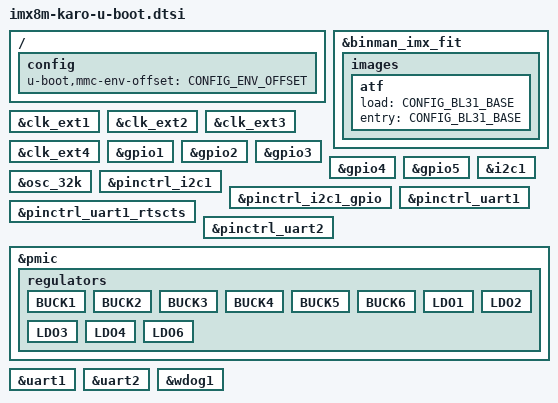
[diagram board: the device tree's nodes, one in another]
// SPDX-License-Identifier: (GPL-2.0 OR MIT)
/*
 * Copyright (C) 2019 Lothar Waßmann <LW@KARO-electronics.de>
 *
 */

/ {
	config {
		u-boot,mmc-env-offset = <CONFIG_ENV_OFFSET>;
	};
};

&binman_imx_fit {
	images {
		atf {
			load = <CONFIG_BL31_BASE>;
			entry = <CONFIG_BL31_BASE>;
		};
	};
};

&clk_ext1 {
	bootph-all;
};

&clk_ext2 {
	bootph-all;
};

&clk_ext3 {
	bootph-all;
};

&clk_ext4 {
	bootph-all;
};

&gpio1 {
	bootph-all;
};

&gpio2 {
	bootph-all;
};

&gpio3 {
	bootph-all;
};

&gpio4 {
	bootph-all;
};

&gpio5 {
	bootph-all;
};

&i2c1 {
	bootph-pre-ram;
};

&osc_32k {
	bootph-all;
};

&pinctrl_i2c1 {
	bootph-pre-ram;
};

&pinctrl_i2c1_gpio {
	bootph-pre-ram;
};

&pinctrl_uart1 {
	bootph-all;
};

&pinctrl_uart1_rtscts {
	bootph-all;
};

&pinctrl_uart2 {
	bootph-all;
};

&pmic {
	regulators {
		BUCK1 {
			bootph-pre-ram;
		};

		BUCK2 {
			bootph-pre-ram;
		};

		BUCK3 {
			bootph-pre-ram;
		};

		BUCK4 {
			bootph-pre-ram;
		};

		BUCK5 {
			bootph-pre-ram;
		};

		BUCK6 {
			bootph-pre-ram;
		};

		LDO1 {
			bootph-pre-ram;
		};

		LDO2 {
			bootph-pre-ram;
		};

		LDO3 {
			bootph-pre-ram;
		};

		LDO4 {
			bootph-pre-ram;
		};

		LDO6 {
			bootph-pre-ram;
		};
	};
};

&uart1 {
	bootph-all;
};

&uart2 {
	bootph-all;
};

&wdog1 {
	bootph-all;
};
